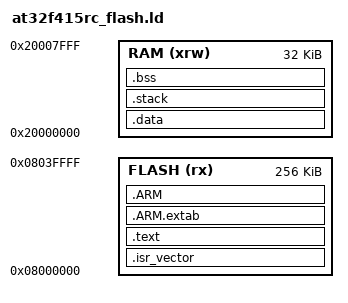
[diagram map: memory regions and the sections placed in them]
/*
*****************************************************************************
**
**  File        : AT32F415xC_FLASH.ld
**
**  Abstract    : Linker script for AT32F415xC Device with
**                256KByte FLASH, 32KByte RAM
**
**                Set stack size according to application requirements.
**
**                Set memory bank area and size if external memory is used.
**
**  Target      : Artery Tek AT32
**
**  Environment : Arm gcc toolchain
**
*****************************************************************************
*/

/* Entry Point */
ENTRY(Reset_Handler)

/* 2048 bytes stack for crt */
_system_stack_size = 0x800;

/* Specify the memory areas */
MEMORY
{
  FLASH (rx)      : ORIGIN = 0x08000000, LENGTH = 256K
  RAM (xrw)       : ORIGIN = 0x20000000, LENGTH = 32K
}

/* Define output sections */
SECTIONS
{
  __link_addr = ORIGIN(FLASH);

  /* The startup code goes first into FLASH */
  .isr_vector :
  {
    . = ALIGN(4);
    KEEP(*(.isr_vector)) /* Startup code */
    . = ALIGN(4);
  } >FLASH
  
  /* The program code and other data goes into FLASH */
  .text :
  {
    . = ALIGN(4);
    *(.text.Reset_Handler)    
    *(.text)           /* .text sections (code) */
    *(.text*)          /* .text* sections (code) */
    *(.rodata)         /* .rodata sections (constants, strings, etc.) */
    *(.rodata*)        /* .rodata* sections (constants, strings, etc.) */
    *(.glue_7)         /* glue arm to thumb code */
    *(.glue_7t)        /* glue thumb to arm code */
    *(.gnu.linkonce.t*)
    
    /* section information for finsh shell */
    . = ALIGN(4);
    __fsymtab_start = .;
    KEEP(*(FSymTab))
    __fsymtab_end = .;

    /* section information for initial. */
    . = ALIGN(4);
    __rt_init_start = .;
    KEEP(*(SORT(.rti_fn*)))
    __rt_init_end = .;

	/* c++ global class constructor */
    . = ALIGN(4);
    PROVIDE(__ctors_start__ = .);
    /* old GCC version uses .ctors */
    KEEP(*(SORT(.ctors.*)))
    KEEP(*(.ctors))
    /* new GCC version uses .init_array */
    KEEP (*(.preinit_array))
    KEEP (*(.init_array))
    KEEP (*(SORT(.init_array.*)))
    PROVIDE(__ctors_end__ = .);
    
    . = ALIGN(4);
    /* c++ global class destructor*/
    PROVIDE(__dtors_start__ = .);
    KEEP (*(.fini_array))
    KEEP(*(SORT(.dtors.*)))
    KEEP(*(.dtors))
    PROVIDE(__dtors_end__ = .);
    
    /*
     * These are the old initialisation sections, intended to contain
     * naked code, with the prologue/epilogue added by crti.o/crtn.o
     * when linking with startup files. The standalone startup code
     * currently does not run these, better use the init arrays below.
     */
    . = ALIGN(4);
    KEEP (*(.init))
    KEEP (*(.fini))

    . = ALIGN(4);
    _etext = .;        /* define a global symbols at end of code */
  } >FLASH


   .ARM.extab   : { *(.ARM.extab* .gnu.linkonce.armextab.*) } >FLASH
    .ARM : {
    __exidx_start = .;
      *(.ARM.exidx*)
      __exidx_end = .;
    } >FLASH

  /* used by the startup to initialize data */
  _sidata = .;

  /* Initialized data sections goes into RAM, load LMA copy after code */
  .data : AT ( _sidata )
  {
    . = ALIGN(4);
    _sdata = .;        /* create a global symbol at data start */
    *(vtable)
    *(.data)           /* .data sections */
    *(.data*)          /* .data* sections */
    *(.gnu.linkonce.d*)
    
    . = ALIGN(4);
	/* All data end */
    _edata = .;        /* define a global symbol at data end */
  } >RAM
  
  .stack ALIGN(4) (NOLOAD) : 
  {
    . = ALIGN(4);
    _sstack = .;
    *(.stack)
    . = . + _system_stack_size;
    . = ALIGN(4);
    _estack = .;
  } >RAM


  /* Uninitialized data section */
  __bss_start = .;
  .bss :
  {
    . = ALIGN(4);
    /* This is used by the startup in order to initialize the .bss secion */
    _sbss = .;
    
    *(.bss)
    *(.bss.*)
    *(COMMON)  /* -fno-common */
    
    . = ALIGN(4);
    /* This is used by the startup in order to initialize the .bss secion */
    _ebss = . ;
    
    *(.bss.init)
  } > RAM
  
  __bss_end = .;
  _end = .;
  
  PROVIDE ( end = _ebss );
  PROVIDE ( _end = _ebss );

  /* Remove information from the standard libraries */
  /DISCARD/ :
  {
    libc.a ( * )
    libm.a ( * )
    libgcc.a ( * )
  }

  /* Stabs debugging sections.  */
  .stab          0 : { *(.stab) }
  .stabstr       0 : { *(.stabstr) }
  .stab.excl     0 : { *(.stab.excl) }
  .stab.exclstr  0 : { *(.stab.exclstr) }
  .stab.index    0 : { *(.stab.index) }
  .stab.indexstr 0 : { *(.stab.indexstr) }
  .comment       0 : { *(.comment) }
    /* DWARF debug sections.
     * Symbols in the DWARF debugging sections are relative to the beginning
     * of the section so we begin them at 0.  */
    /* DWARF 1 */
  .debug          0 : { *(.debug) }
  .line           0 : { *(.line) }
    /* GNU DWARF 1 extensions */
  .debug_srcinfo  0 : { *(.debug_srcinfo) }
  .debug_sfnames  0 : { *(.debug_sfnames) }
    /* DWARF 1.1 and DWARF 2 */
  .debug_aranges  0 : { *(.debug_aranges) }
  .debug_pubnames 0 : { *(.debug_pubnames) }
    /* DWARF 2 */
  .debug_info     0 : { *(.debug_info .gnu.linkonce.wi.*) }
  .debug_abbrev   0 : { *(.debug_abbrev) }
  .debug_line     0 : { *(.debug_line) }
  .debug_frame    0 : { *(.debug_frame) }
  .debug_str      0 : { *(.debug_str) }
  .debug_loc      0 : { *(.debug_loc) }
  .debug_macinfo  0 : { *(.debug_macinfo) }
    /* SGI/MIPS DWARF 2 extensions */
  .debug_weaknames 0 : { *(.debug_weaknames) }
  .debug_funcnames 0 : { *(.debug_funcnames) }
  .debug_typenames 0 : { *(.debug_typenames) }
  .debug_varnames  0 : { *(.debug_varnames) }
}
